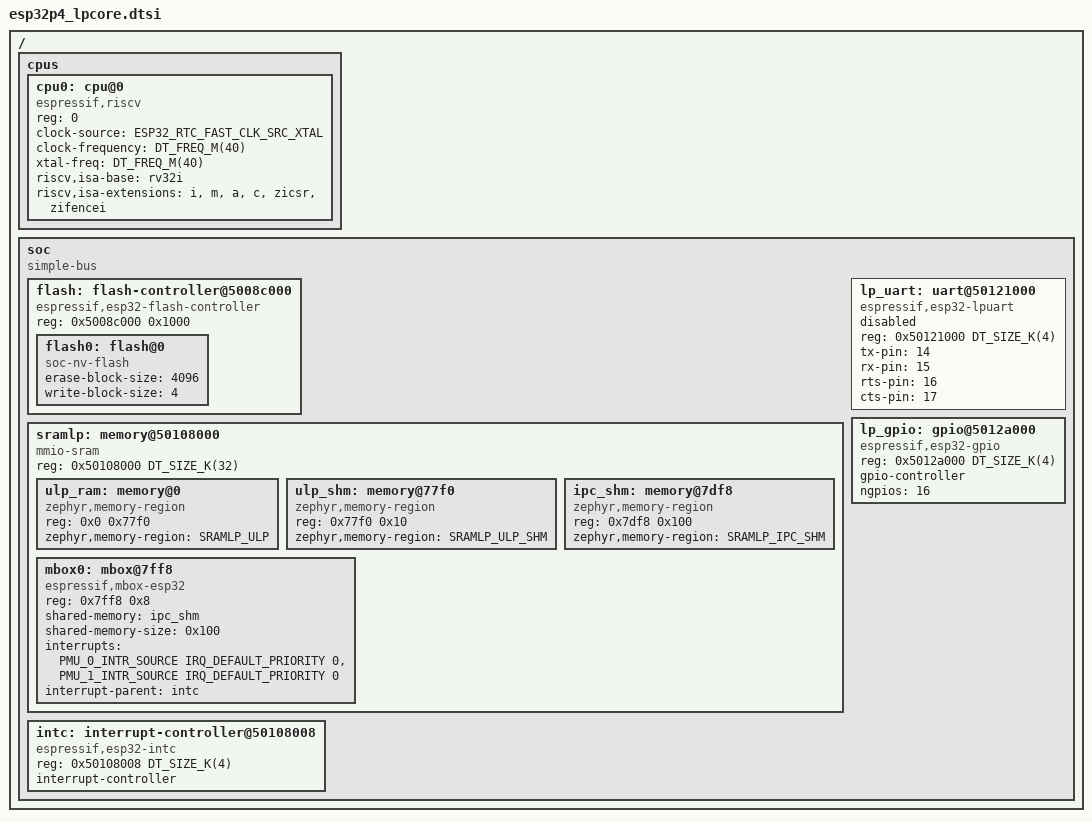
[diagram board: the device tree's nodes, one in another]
/*
 * Copyright (c) 2026 Espressif Systems (Shanghai) Co., Ltd.
 *
 * SPDX-License-Identifier: Apache-2.0
 */
#include <mem.h>
#include <freq.h>
#include <zephyr/dt-bindings/gpio/gpio.h>
#include <zephyr/dt-bindings/interrupt-controller/esp-esp32p4-intmux.h>
#include <zephyr/dt-bindings/clock/esp32p4_clock.h>

/ {
	#address-cells = <1>;
	#size-cells = <1>;

	cpus {
		#address-cells = <1>;
		#size-cells = <0>;

		cpu0: cpu@0 {
			compatible = "espressif,riscv", "riscv";
			reg = <0>;
			device_type = "cpu";
			clock-source = <ESP32_RTC_FAST_CLK_SRC_XTAL>;
			clock-frequency = <DT_FREQ_M(40)>;
			xtal-freq = <DT_FREQ_M(40)>;
			riscv,isa-base = "rv32i";
			riscv,isa-extensions = "i", "m", "a", "c", "zicsr", "zifencei";
		};
	};

	soc {
		compatible = "simple-bus";
		ranges;
		#address-cells = <1>;
		#size-cells = <1>;

		flash: flash-controller@5008c000 {
			compatible = "espressif,esp32-flash-controller";
			reg = <0x5008c000 0x1000>;
			ranges;
			#address-cells = <1>;
			#size-cells = <1>;

			flash0: flash@0 {
				compatible = "soc-nv-flash";
				erase-block-size = <4096>;
				write-block-size = <4>;
				#address-cells = <1>;
				#size-cells = <1>;
				/* reg and ranges are specified in SOC/SIP dtsi */
			};
		};

		sramlp: memory@50108000 {
			compatible = "mmio-sram";
			reg = <0x50108000 DT_SIZE_K(32)>;
			ranges = <0x0 0x50108000 DT_SIZE_K(32)>;
			#address-cells = <1>;
			#size-cells = <1>;

			ulp_ram: memory@0 {
				compatible = "zephyr,memory-region", "mmio-sram";
				reg = <0x0 0x77f0>;
				zephyr,memory-region = "SRAMLP_ULP";
			};

			ulp_shm: memory@77f0 {
				compatible = "zephyr,memory-region", "mmio-sram";
				reg = <0x77f0 0x10>;
				zephyr,memory-region = "SRAMLP_ULP_SHM";
			};

			ipc_shm: memory@7df8 {
				compatible = "zephyr,memory-region", "mmio-sram";
				reg = <0x7df8 0x100>;
				zephyr,memory-region = "SRAMLP_IPC_SHM";
			};

			mbox0: mbox@7ff8 {
				compatible = "espressif,mbox-esp32";
				reg = <0x7ff8 0x8>;
				shared-memory = <&ipc_shm>;
				shared-memory-size = <0x100>;
				interrupts = <PMU_0_INTR_SOURCE IRQ_DEFAULT_PRIORITY 0>,
					     <PMU_1_INTR_SOURCE IRQ_DEFAULT_PRIORITY 0>;
				interrupt-parent = <&intc>;
				#mbox-cells = <1>;
				status = "okay";
			};
		};

		intc: interrupt-controller@50108008 {
			compatible = "espressif,esp32-intc";
			reg = <0x50108008 DT_SIZE_K(4)>;
			#address-cells = <0>;
			#interrupt-cells = <3>;
			interrupt-controller;
			status = "okay";
		};

		lp_uart: uart@50121000 {
			compatible = "espressif,esp32-lpuart";
			reg = <0x50121000 DT_SIZE_K(4)>;
			tx-pin = <14>;
			rx-pin = <15>;
			rts-pin = <16>;
			cts-pin = <17>;
			status = "disabled";
		};

		lp_gpio: gpio@5012a000 {
			compatible = "espressif,esp32-gpio";
			reg = <0x5012a000 DT_SIZE_K(4)>;
			gpio-controller;
			#gpio-cells = <2>;
			ngpios = <16>;
		};
	};
};
